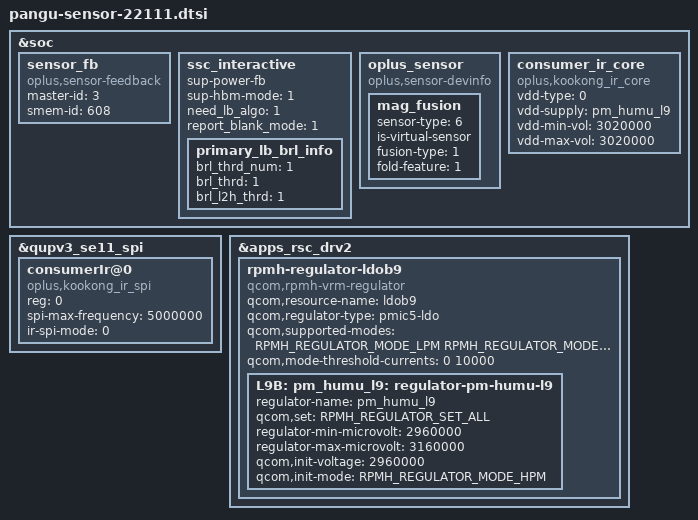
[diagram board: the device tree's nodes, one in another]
/**********************************************************************************
* Copyright (c)  2022-2024  Guangdong oplus Mobile Comm Corp., Ltd
* Description: oplus sensor dtsi
*
* Version: 1.0
* Date: 2022-07-04
*
* ------------------------------ Revision History: --------------------------------
* <version>         <date>        <author>                <desc>
***********************************************************************************/
#include <dt-bindings/regulator/qcom,rpmh-regulator-levels.h>
&soc {
	//#ifdef OPLUS_FEATURE_SENSOR_SMEM
	sensor_fb: sensor_fb {
		compatible = "oplus,sensor-feedback";
		master-id  = <3>;
		smem-id    = <608>;
	};
	ssc_interactive {
		sup-power-fb;
		sup-hbm-mode = <1>;
		need_lb_algo = <1>;
		report_blank_mode = <1>;

		primary_lb_brl_info {
			brl_thrd_num = <1>;
			brl_thrd = <1>;
			brl_l2h_thrd = <1>;
		};
    };
	oplus_sensor {
		compatible = "oplus,sensor-devinfo";
		/*virtual sensor*/
		mag_fusion {
			sensor-type = <6>;//OPLUS_MAG_FUSION
			is-virtual-sensor;
			fusion-type = <1>;//AKM_FUSION
			fold-feature = <1>;
		};
	};
	consumer_ir_core {
		compatible = "oplus,kookong_ir_core";
		status = "okay";
		vdd-type = <0>; /*0: internal LDO , 1: external LOD*/
		vdd-supply = <&pm_humu_l9>;
		vdd-min-vol = <3020000>;
		vdd-max-vol = <3020000>;
	};
	//#endif /*OPLUS_FEATURE_SENSOR_SMEM*/
};

//add for oplus consumerIr SPI mode
&qupv3_se11_spi{
	status = "ok";
	consumerIr@0 {
		compatible = "oplus,kookong_ir_spi";
		reg = <0>;
		status = "ok";

		spi-max-frequency = <5000000>;    /*4800000,9600000,15000000,19200000*/
		ir-spi-mode = <0>;
	};
};

&apps_rsc_drv2 {
	rpmh-regulator-ldob9 {
		compatible = "qcom,rpmh-vrm-regulator";
		qcom,resource-name = "ldob9";
		qcom,regulator-type = "pmic5-ldo";
		qcom,supported-modes =
			<RPMH_REGULATOR_MODE_LPM
			 RPMH_REGULATOR_MODE_HPM>;
		qcom,mode-threshold-currents = <0 10000>;

		L9B: pm_humu_l9: regulator-pm-humu-l9 {
			regulator-name = "pm_humu_l9";
			qcom,set = <RPMH_REGULATOR_SET_ALL>;
			regulator-min-microvolt = <2960000>;
			regulator-max-microvolt = <3160000>;
			qcom,init-voltage = <2960000>;
			qcom,init-mode = <RPMH_REGULATOR_MODE_HPM>;
		};
	};
};

